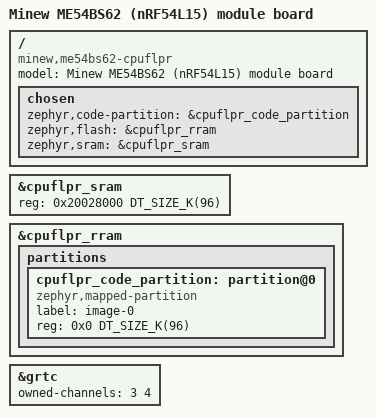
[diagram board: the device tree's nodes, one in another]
/dts-v1/;

#include <nordic/nrf54l15_cpuflpr.dtsi>
#include "me54bs62-pinctrl.dtsi"

/ {
	model = "Minew ME54BS62 (nRF54L15) module board";
	compatible = "minew,me54bs62-cpuflpr";

	chosen {
		zephyr,code-partition = &cpuflpr_code_partition;
		zephyr,flash = &cpuflpr_rram;
		zephyr,sram = &cpuflpr_sram;
	};
};

&cpuflpr_sram {
	status = "okay";
	reg = <0x20028000 DT_SIZE_K(96)>;
	ranges = <0x0 0x20028000 DT_SIZE_K(96)>;
};

&cpuflpr_rram {
	partitions {
		#address-cells = <1>;
		#size-cells = <1>;
		ranges;

		cpuflpr_code_partition: partition@0 {
			compatible = "zephyr,mapped-partition";
			label = "image-0";
			reg = <0x0 DT_SIZE_K(96)>;
		};
	};
};

&grtc {
	owned-channels = <3 4>;
	status = "okay";
};
